# PY32F002Bxx register map
Vendor: Puya; Series: PY32F0; File version: 1.0.0
CPU: CM0+ r0p1, little endian, no MPU, no FPU, 4 interrupt priority bits
Registers are 32-bit, read-write, reset 0x0 unless marked. A register's access mark holds for its fields unless they carry their own. Offsets are from the block's base; [hi:lo] are bit positions.

## FLASH
Base 0x40022000
0x00 ACR reset 0x600 — Access control register
  [0] LATENCY
    0=WS0 (0 wait states); 1=WS1 (1 wait state)
0x08 KEYR wo — Flash key register
  [31:0] KEY — Flash key
0x0C OPTKEYR wo — Option byte key register
  [31:0] OPTKEY — Option byte key
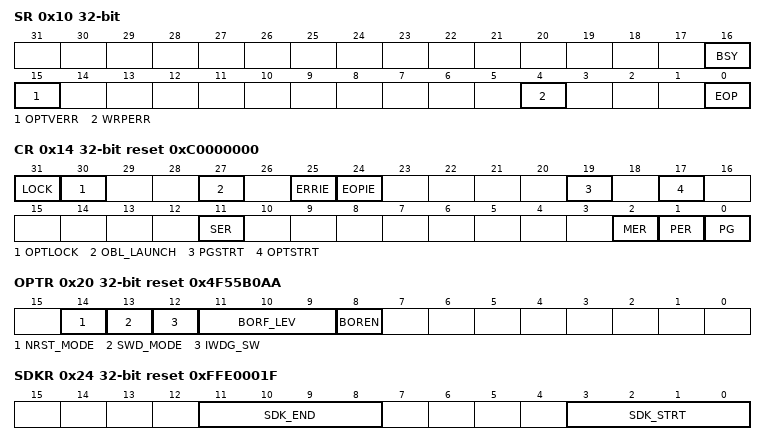
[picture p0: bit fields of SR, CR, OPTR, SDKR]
0x10 SR — Status register
  [16] BSY — Busy
    on read: 0=Inactive (No write/erase operation is in progress); 1=Active (A write/erase operation is in progress)
  [15] OPTVERR — Option and Engineering bits loading validity error
    0=NoError (No option and Engineering bits loading validity error occurred); 1=Error (An option and Engineering bits loading validity error occurred)
  [4] WRPERR — Write protected error
    0=NoError (No write protection error occurred); 1=Error (A write protection error occurred)
  [0] EOP — End of operation
    0=NoEvent (No EOP operation occurred); 1=Event (An EOP event occurred)
0x14 CR reset 0xC0000000 — Flash control register
  [31] LOCK — FLASH_CR Lock
    0=Unlocked (FLASH_CR register is unlocked); 1=Locked (FLASH_CR register is locked)
  [30] OPTLOCK — Options Lock
    0=Unlocked (Options is unlocked); 1=Locked (Options is locked)
  [27] OBL_LAUNCH — Force the option byte loading
    0=Inactive (Force option byte loading inactive); 1=Active (Force option byte loading active)
  [25] ERRIE — Error interrupt enable
    0=Disabled (Error interrupt generation disabled); 1=Enabled (Error interrupt generation enabled)
  [24] EOPIE — End of operation interrupt enable
    0=Disabled (End of operation interrupt disabled); 1=Enabled (End of operation interrupt enabled)
  [19] PGSTRT — Flash main memory program start
    1=Start (Flash main memory program start)
  [17] OPTSTRT — Option byte program start
    1=Option byte program start
  [11] SER — Sector erase
    1=SectorErase (Erase activated for user sectors)
  [2] MER — Mass erase
    1=MassErase (Erase activated for all user sectors)
  [1] PER — Page erase
    1=PageErase (Erase activated for selected page)
  [0] PG — Programming
    1=Program (Flash programming activated)
0x20 OPTR reset 0x4F55B0AA — Flash option register
  [14] NRST_MODE
    0=NRST (Configure pin mode together with SWD_MODE); 1=GPIO (Configure pin mode together with SWD_MODE)
  [13] SWD_MODE
    0=SWD (Configure pin mode together with NRST_MODE); 1=GPIO (Configure pin mode together with NRST_MODE)
  [12] IWDG_SW — Independent watchdog selection
    0=Hardware independent watchdog; 1=Software independent watchdog
  [11:9] BORF_LEV — These bits contain the VDD supply level threshold that activates the reset
    0=Level0 (BOR level 0. Reset level threshold is around 1.8 V); 1=Level1 (BOR level 1. Reset level threshold is around 2.0 V); 2=Level2 (BOR level 2. Reset level threshold is around 2.2 V); 3=Level3 (BOR level 3. Reset level threshold is around 2.4 V); 4=Level4 (BOR level 4. Reset level threshold is around 2.6 V); 5=Level5 (BOR level 5. Reset level threshold is around 2.8 V); 6=Level6 (BOR level 6. Reset level threshold is around 3.0 V); 7=Level7 (BOR level 7. Reset level threshold is around 3.2 V)
  [8] BOREN — BOR reset Level
    0=Disabled (BOR disabled); 1=Enabled (BOR enabled)
0x24 SDKR reset 0xFFE0001F — Flash SDK address register
  [11:8] SDK_END — SDK area end address
  [3:0] SDK_STRT — SDK area start address
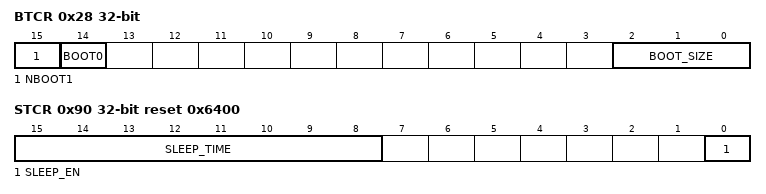
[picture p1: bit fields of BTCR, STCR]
0x28 BTCR — FLASH boot control register
  [15] NBOOT1
    0=SRAM (Select boot mode together with BOOT0); 1=LoadFlash (Select boot mode together with BOOT0)
  [14] BOOT0
    0=MainFlash (Boot from main flash); 1=BOOT1 (Select boot mode together with nBOOT1)
  [2:0] BOOT_SIZE
    0=No load flash area; 1=Boot_1K (Boot size = 1K 0x08005C00~0x08005FFF); 2=Boot_2K (Boot size = 2K 0x08005800~0x08005FFF); 3=Boot_3K (Boot size = 3K 0x08005400~0x08005FFF); 4=Boot_4K (Boot size = 4K 0x08005000~0x08005FFF)
0x2C WRPR reset 0xFFFF — Flash WRP address register
  [5:0] WRP range 0..31 — WRP address
0x90 STCR reset 0x6400 — Flash sleep time config register
  [15:8] SLEEP_TIME — FLash sleep time configuration(counter based on HSI_10M)
  [0] SLEEP_EN — FLash sleep enable
0x100 TS0 reset 0xB4 — Flash TS0 register
  [8:0] TS0 — FLash TS0 register
0x104 TS1 reset 0x1B0 — Flash TS1 register
  [9:0] TS1 — FLash TS1 register
0x108 TS2P reset 0xB4 — Flash TS2P register
  [8:0] TS2P — FLash TS2P register
0x10C TPS3 reset 0x6C0 — Flash TPS3 register
  [11:0] TPS3 — FLash TPS3 register
0x110 TS3 reset 0xB4 — Flash TS3 register
  [8:0] TS3 — FLash TS3 register
0x114 PERTPE reset 0x14820 — Flash PERTPE register
  [17:0] PERTPE — FLash PERTPE register
0x118 SMERTPE reset 0x14820 — Flash SMERTPE register
  [17:0] SMERTPE — FLash SMERTPE register
0x11C PRGTPE reset 0x5DC0 — Flash PRGTPE register
  [15:0] PRGTPE — FLash PRGTPE register
0x120 PRETPE reset 0x12C0 — Flash PRETPE register
  [13:0] PRETPE — FLash PRETPE register
